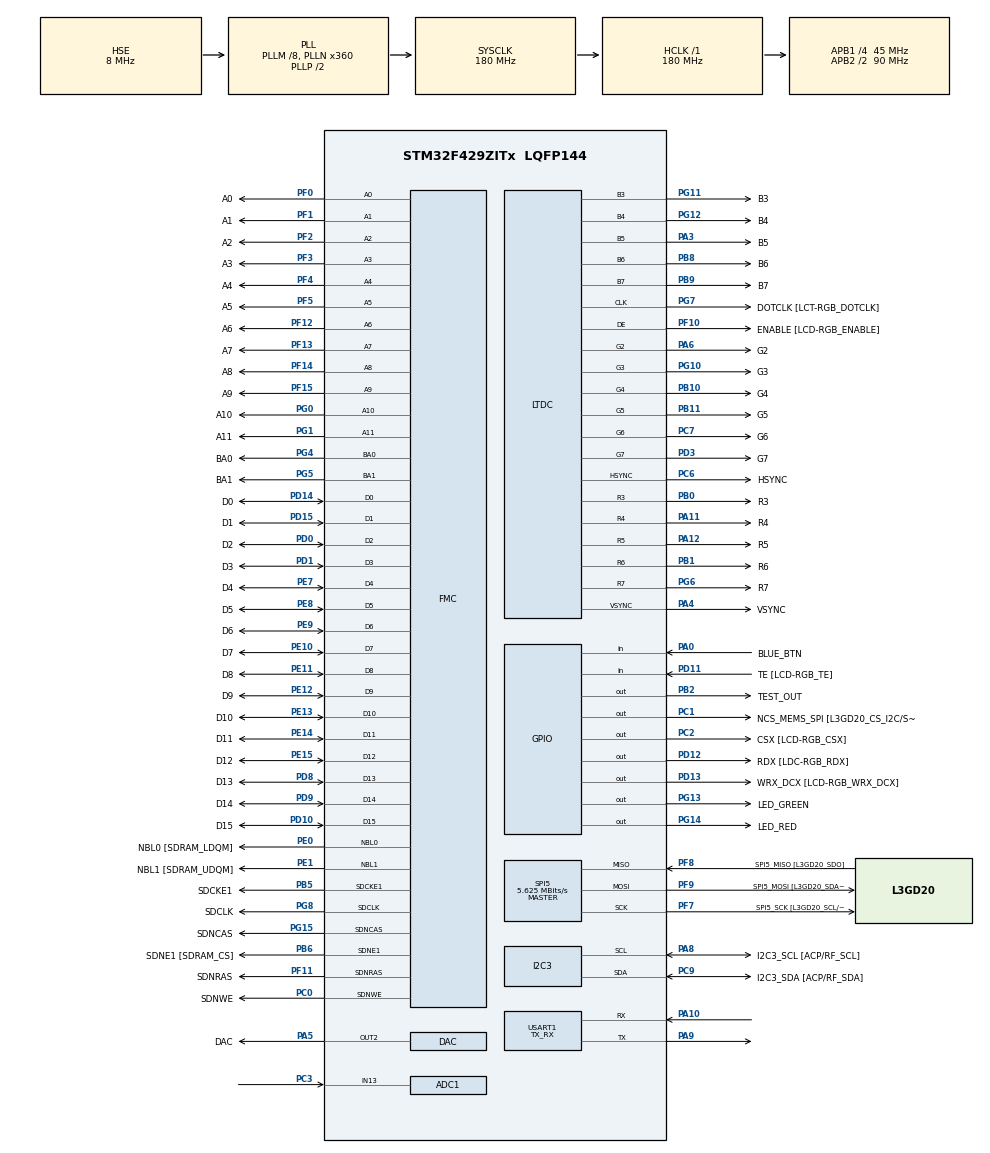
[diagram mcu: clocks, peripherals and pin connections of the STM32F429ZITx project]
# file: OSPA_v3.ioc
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PF5.GPIO_PuPd=GPIO_NOPULL
VP_TIM5_VS_ClockSourceINT.Mode=Internal
PD12.GPIO_Label=RDX [LDC-RGB_RDX]
PC10.GPIO_PuPd=GPIO_NOPULL
FMC.SDClockPeriod2=FMC_SDRAM_CLOCK_PERIOD_2
FMC.SDClockPeriod1=FMC_SDRAM_CLOCK_PERIOD_2
SH.FMC_A0.0=FMC_A0,12b-sda1
PB10.GPIO_PuPd=GPIO_NOPULL
PG8.Signal=FMC_SDCLK
PG0.Signal=FMC_A10
PA3.GPIO_PuPd=GPIO_NOPULL
PE10.GPIO_PuPd=GPIO_NOPULL
PD10.GPIO_PuPd=GPIO_NOPULL
SH.FMC_D5_DA5.0=FMC_D5,sd-16b-d1
PF10.GPIO_PuPd=GPIO_NOPULL
PG10.GPIO_PuPd=GPIO_NOPULL
PA6.GPIO_Mode=GPIO_MODE_AF_PP
SH.FMC_D9_DA9.0=FMC_D9,sd-16b-d1
PG13.GPIO_Mode=GPIO_MODE_OUTPUT_PP
PE13.GPIO_Mode=GPIO_MODE_AF_PP
PF13.GPIO_Mode=GPIO_MODE_AF_PP
PG15.GPIO_Label=SDNCAS
PA4.Mode=RGB565
PF7.Signal=SPI5_SCK
PD13.GPIO_Mode=GPIO_MODE_OUTPUT_PP
NVIC.DMA2D_IRQn=true\:5\:0\:true\:false\:true\:true\:true
SH.FMC_SDNWE.0=FMC_SDNWE,12b-sda1
SH.FMC_D11_DA11.0=FMC_D11,sd-16b-d1
PG7.GPIO_Mode=GPIO_MODE_AF_PP
RCC.APB2TimFreq_Value=180000000
PB6.Signal=FMC_SDNE1
Dma.ADC1.0.Direction=DMA_PERIPH_TO_MEMORY
PC7.Signal=LTDC_G6
PD0.Signal=FMC_D2_DA2
PD8.Signal=FMC_D13_DA13
PE1.Signal=FMC_NBL1
Dma.ADC1.0.MemDataAlignment=DMA_MDATAALIGN_WORD
PF1.GPIO_Label=A1
PC1.GPIO_PuPd=GPIO_NOPULL
PD1.GPIO_Label=D3
FMC.SelfRefreshTime1=4
PF12.GPIO_Label=A6
LTDC.PixelFormat_L0=LTDC_PIXEL_FORMAT_RGB565
LTDC.PixelFormat_L1=LTDC_PIXEL_FORMAT_RGB565
PB1.GPIO_Speed=GPIO_SPEED_FREQ_LOW
PE9.Signal=FMC_D6_DA6
PD1.GPIO_Speed=GPIO_SPEED_FREQ_VERY_HIGH
SH.FMC_A2.0=FMC_A2,12b-sda1
PB1.GPIO_Label=R6
PG4.GPIO_Label=BA0
PC9.Mode=I2C
PD14.GPIO_PuPd=GPIO_NOPULL
PA8.Signal=I2C3_SCL
SH.FMC_D1_DA1.0=FMC_D1,sd-16b-d1
PF1.GPIO_Speed=GPIO_SPEED_FREQ_VERY_HIGH
PF1.GPIO_Mode=GPIO_MODE_AF_PP
LTDC.HSync=10
PF14.GPIO_PuPd=GPIO_NOPULL
PG0.GPIO_PuPd=GPIO_NOPULL
PE9.GPIO_Mode=GPIO_MODE_AF_PP
Mcu.Package=LQFP144
PB9.Signal=LTDC_B7
TIM2.Prescaler=499
PB1.Signal=LTDC_R6
PD12.Signal=GPIO_Output
PA10.Signal=USART1_RX
PB9.GPIO_PuPd=GPIO_NOPULL
PE12.GPIO_Label=D9
FMC.WriteRecoveryTime1=3
PE12.GPIO_Speed=GPIO_SPEED_FREQ_VERY_HIGH
PB5.GPIO_Speed=GPIO_SPEED_FREQ_VERY_HIGH
SPI5.CalculateBaudRate=5.625 MBits/s
PE8.GPIO_Speed=GPIO_SPEED_FREQ_VERY_HIGH
PG8.GPIO_Speed=GPIO_SPEED_FREQ_VERY_HIGH
RCC.APB2CLKDivider=RCC_HCLK_DIV2
LTDC.VSync=2
PF5.GPIO_Speed=GPIO_SPEED_FREQ_VERY_HIGH
RCC.APB1TimFreq_Value=90000000
FMC.RowCycleDelay2=7
PF10.Mode=RGB565
FMC.RowCycleDelay1=7
PD3.GPIO_PuPd=GPIO_NOPULL
PF9.GPIO_PuPd=GPIO_NOPULL
NVIC.DMA1_Stream6_IRQn=true\:0\:0\:false\:false\:true\:false\:true
PA4.GPIO_Label=VSYNC
PA8.GPIO_Speed=GPIO_SPEED_FREQ_LOW
PD15.Signal=FMC_D1_DA1
PG12.Signal=LTDC_B4
PB5.GPIO_Mode=GPIO_MODE_AF_PP
SH.FMC_A4.0=FMC_A4,12b-sda1
PF4.GPIO_Mode=GPIO_MODE_AF_PP
PG5.Signal=FMC_A15_BA1
SH.FMC_D10_DA10.0=FMC_D10,sd-16b-d1
PB6.GPIO_PuPd=GPIO_NOPULL
PD3.Signal=LTDC_G7
PC2.Signal=GPIO_Output
PF5.GPIO_Mode=GPIO_MODE_AF_PP
LTDC.ImageWidth_L1=240
PG8.GPIO_PuPd=GPIO_NOPULL
PF8.GPIO_Label=SPI5_MISO [L3GD20_SDO]
LTDC.ImageWidth_L0=240
PD10.Signal=FMC_D15_DA15
PA3.Mode=RGB565
PC10.GPIO_Mode=GPIO_MODE_AF_PP
PB8.GPIO_Label=B6
PB10.GPIO_Mode=GPIO_MODE_AF_PP
PA8.GPIO_Label=I2C3_SCL [ACP/RF_SCL]
PE8.GPIO_Label=D5
Dma.ADC1.0.Priority=DMA_PRIORITY_VERY_HIGH
PB1.GPIO_Mode=GPIO_MODE_AF_PP
PG10.GPIO_Mode=GPIO_MODE_AF_PP
PA5.Signal=COMP_DAC2_group
PF10.GPIO_Mode=GPIO_MODE_AF_PP
PE1.GPIO_Label=NBL1 [SDRAM_UDQM]
PF15.GPIO_Speed=GPIO_SPEED_FREQ_VERY_HIGH
PF13.GPIO_PuPd=GPIO_NOPULL
FMC.ReadBurst1=FMC_SDRAM_RBURST_DISABLE
SH.FMC_A6.0=FMC_A6,12b-sda1
PE14.Signal=FMC_D11_DA11
PF12.GPIO_Speed=GPIO_SPEED_FREQ_VERY_HIGH
PG7.GPIO_Label=DOTCLK [LCT-RGB_DOTCLK]
PF4.GPIO_Label=A4
PC9.GPIO_PuPd=GPIO_NOPULL
PC1.GPIO_Speed=GPIO_SPEED_FREQ_LOW
PF13.Signal=FMC_A7
TIM2.Period=1439
PG14.GPIO_PuPd=GPIO_NOPULL
PG1.GPIO_Speed=GPIO_SPEED_FREQ_VERY_HIGH
ADC1.ExternalTrigConv=ADC_EXTERNALTRIGCONV_T2_TRGO
PC7.GPIO_Label=G6
ADC1.master=1
PA5.GPIO_Label=DAC
PB5.GPIO_PuPd=GPIO_NOPULL
ProjectManager.HeapSize=0x10
PB1.Mode=RGB565
PD0.GPIO_PuPd=GPIO_NOPULL
PG12.GPIO_Speed=GPIO_SPEED_FREQ_LOW
Dma.DAC2.1.Mode=DMA_CIRCULAR
PD8.GPIO_Speed=GPIO_SPEED_FREQ_VERY_HIGH
NVIC.PriorityGroup=NVIC_PRIORITYGROUP_4
PF0.GPIO_Label=A0
PE15.GPIO_Speed=GPIO_SPEED_FREQ_VERY_HIGH
PF4.Signal=FMC_A4
PD14.GPIO_Mode=GPIO_MODE_AF_PP
PG5.GPIO_Speed=GPIO_SPEED_FREQ_VERY_HIGH
Mcu.Family=STM32F4
LTDC.BlendingFactor1_L1=LTDC_BLENDING_FACTOR1_PAxCA
LTDC.BlendingFactor1_L0=LTDC_BLENDING_FACTOR1_CA
PA6.Mode=RGB565
SH.FMC_A8.0=FMC_A8,12b-sda1
SH.FMC_D14_DA14.0=FMC_D14,sd-16b-d1
PE11.GPIO_Label=D8
PD9.GPIO_Speed=GPIO_SPEED_FREQ_VERY_HIGH
PD0.GPIO_Label=D2
PA11.Mode=RGB565
PF9.GPIO_Speed=GPIO_SPEED_FREQ_LOW
PC2.GPIO_Speed=GPIO_SPEED_FREQ_LOW
SH.FMC_A14_BA0.0=FMC_BA0,FourSdramBanks1
SH.FMC_A11.0=FMC_A11,12b-sda1
PD8.GPIO_PuPd=GPIO_NOPULL
PG5.GPIO_Label=BA1
PG11.Signal=LTDC_B3
PG15.Signal=FMC_SDNCAS
SH.COMP_DAC2_group.0=DAC_OUT2,DAC_OUT2
PD13.Signal=GPIO_Output
PE11.GPIO_PuPd=GPIO_NOPULL
PF11.GPIO_PuPd=GPIO_NOPULL
PB1.GPIO_PuPd=GPIO_NOPULL
PF13.GPIO_Speed=GPIO_SPEED_FREQ_VERY_HIGH
LTDC.WindowX1_L1=240
SH.FMC_NBL1.0=FMC_NBL1,Sd2ByteEnable1
LTDC.WindowX1_L0=240
PG5.GPIO_PuPd=GPIO_NOPULL
RCC.HSE_VALUE=8000000
PA4.GPIO_PuPd=GPIO_NOPULL
FMC.ExitSelfRefreshDelay1=7
PF7.GPIO_Mode=GPIO_MODE_AF_PP
PE13.GPIO_PuPd=GPIO_NOPULL
PA4.GPIO_Speed=GPIO_SPEED_FREQ_LOW
PG11.GPIO_Speed=GPIO_SPEED_FREQ_LOW
PH1/OSC_OUT.GPIO_Label=PH1-OSC_OUT
PA6.GPIO_PuPd=GPIO_NOPULL
PF9.Mode=Full_Duplex_Master
PF7.GPIO_Speed=GPIO_SPEED_FREQ_LOW
PF8.GPIO_PuPd=GPIO_NOPULL
PF11.Signal=FMC_SDNRAS
PB5.Mode=SdramChipSelect2_1
PC7.GPIO_Mode=GPIO_MODE_AF_PP
PG7.GPIO_PuPd=GPIO_NOPULL
PD10.GPIO_Speed=GPIO_SPEED_FREQ_VERY_HIGH
PG4.GPIO_Mode=GPIO_MODE_AF_PP
Dma.DAC2.1.Instance=DMA1_Stream6
PD6.GPIO_Mode=GPIO_MODE_AF_PP
PD13.GPIO_Label=WRX_DCX [LCD-RGB_WRX_DCX]
PA6.Signal=LTDC_G2
PB0.GPIO_Mode=GPIO_MODE_AF_PP
RCC.EnbaleCSS=true
PG1.GPIO_PuPd=GPIO_NOPULL
PF8.Signal=SPI5_MISO
PG0.GPIO_Label=A10
PB5.GPIO_Label=SDCKE1
Dma.Request1=DAC2
PD0.GPIO_Mode=GPIO_MODE_AF_PP
PG14.GPIO_Mode=GPIO_MODE_OUTPUT_PP
PG11.GPIO_Label=B3
PD3.GPIO_Label=G7
PE14.GPIO_Mode=GPIO_MODE_AF_PP
PE7.Signal=FMC_D4_DA4
DAC.TriangleAmplitude2=DAC_TRIANGLEAMPLITUDE_127
PD6.Signal=LTDC_B2
Dma.Request0=ADC1
PF3.GPIO_Label=A3
PA12.GPIO_Speed=GPIO_SPEED_FREQ_LOW
PA3.Signal=LTDC_B5
PE0.GPIO_PuPd=GPIO_NOPULL
PG1.GPIO_Mode=GPIO_MODE_AF_PP
NVIC.LTDC_IRQn=true\:5\:0\:true\:false\:true\:true\:true
SH.ADCx_IN13.0=ADC1_IN13,IN13
LTDC.VFP=4
PD15.GPIO_Label=D1
LTDC.WindowY1_L0=320
PG7.Signal=LTDC_CLK
LTDC.WindowY1_L1=320
PA10.Mode=Asynchronous
PC9.GPIO_Label=I2C3_SDA [ACP/RF_SDA]
Dma.DAC2.1.FIFOMode=DMA_FIFOMODE_DISABLE
PF10.GPIO_Speed=GPIO_SPEED_FREQ_LOW
PE14.GPIO_Label=D11
PD9.Signal=FMC_D14_DA14
SPI5.Mode=SPI_MODE_MASTER
PA12.GPIO_Label=R5
PD8.GPIO_Label=D13
PB0.GPIO_Speed=GPIO_SPEED_FREQ_LOW
PG8.GPIO_Label=SDCLK
Dma.ADC1.0.PeriphDataAlignment=DMA_PDATAALIGN_WORD
PA9.Mode=Asynchronous
PB2/BOOT1.Signal=GPIO_Output
PB10.GPIO_Label=G4
PC9.GPIO_Mode=GPIO_MODE_AF_OD
SH.FMC_D13_DA13.0=FMC_D13,sd-16b-d1
PA3.GPIO_Mode=GPIO_MODE_AF_PP
PG0.GPIO_Speed=GPIO_SPEED_FREQ_VERY_HIGH
PB9.Mode=RGB565
PF9.GPIO_Label=SPI5_MOSI [L3GD20_SDA/SDI/SDO]
PD10.GPIO_Label=D15
PE10.GPIO_Mode=GPIO_MODE_AF_PP
board=STM32F429I-DISC1
PD13.GPIO_Speed=GPIO_SPEED_FREQ_LOW
PG12.Mode=RGB565
PC7.GPIO_Speed=GPIO_SPEED_FREQ_LOW
RCC.VCOOutputFreq_Value=360000000
ADC1.EnableAnalogWatchDog=true
PA4.GPIO_Mode=GPIO_MODE_AF_PP
Dma.DAC2.1.PeriphDataAlignment=DMA_PDATAALIGN_WORD
PF4.GPIO_Speed=GPIO_SPEED_FREQ_VERY_HIGH
PC1.GPIO_Label=NCS_MEMS_SPI [L3GD20_CS_I2C/SPI]
PE11.GPIO_Mode=GPIO_MODE_AF_PP
SH.FMC_D12_DA12.0=FMC_D12,sd-16b-d1
PF15.GPIO_Label=A9
PE14.GPIO_PuPd=GPIO_NOPULL
PF1.Signal=FMC_A1
PF8.GPIO_Mode=GPIO_MODE_AF_PP
PE0.Signal=FMC_NBL0
PE7.GPIO_Label=D4
PE12.Signal=FMC_D9_DA9
PE12.GPIO_Mode=GPIO_MODE_AF_PP
Dma.DAC2.1.Direction=DMA_MEMORY_TO_PERIPH
RCC.48MHZClocksFreq_Value=120000000
RCC.SYSCLKFreq_VALUE=180000000
TIM5.Prescaler=99
Dma.ADC1.0.MemInc=DMA_MINC_ENABLE
PE15.GPIO_PuPd=GPIO_NOPULL
PG4.GPIO_PuPd=GPIO_NOPULL
PD3.GPIO_Mode=GPIO_MODE_AF_PP
RCC.HSI_VALUE=16000000
PA8.GPIO_PuPd=GPIO_NOPULL
PH0/OSC_IN.GPIO_Label=PH0-OSC_IN
PF9.GPIO_Mode=GPIO_MODE_AF_PP
RCC.PLLQ=3
RCC.PLLM=8
RCC.PLLN=360
TIM5.Period=44
PG0.GPIO_Mode=GPIO_MODE_AF_PP
PB8.GPIO_Speed=GPIO_SPEED_FREQ_LOW
PD6.GPIO_Speed=GPIO_SPEED_FREQ_LOW
PG14.GPIO_Speed=GPIO_SPEED_FREQ_LOW
LTDC.ImageHeight_L0=320
LTDC.ImageHeight_L1=320
PB0.GPIO_PuPd=GPIO_NOPULL
PA3.GPIO_Label=B5
PD6.GPIO_PuPd=GPIO_NOPULL
PA11.GPIO_Speed=GPIO_SPEED_FREQ_LOW
PF15.GPIO_Mode=GPIO_MODE_AF_PP
SH.FMC_D7_DA7.0=FMC_D7,sd-16b-d1
PE15.GPIO_Mode=GPIO_MODE_AF_PP
PD1.GPIO_Mode=GPIO_MODE_AF_PP
PD15.GPIO_Mode=GPIO_MODE_AF_PP
PE14.GPIO_Speed=GPIO_SPEED_FREQ_VERY_HIGH
FMC.RCDDelay1=2
PB10.Mode=RGB565
PA8.GPIO_Mode=GPIO_MODE_AF_OD
PG4.Signal=FMC_A14_BA0
PG6.GPIO_Label=R7
PE8.GPIO_PuPd=GPIO_NOPULL
FMC.LoadToActiveDelay1=2
PC6.GPIO_Label=HSYNC
PA6.GPIO_Label=G2
PB6.GPIO_Label=SDNE1 [SDRAM_CS]
PA3.GPIO_Speed=GPIO_SPEED_FREQ_LOW
PD3.GPIO_Speed=GPIO_SPEED_FREQ_LOW
PG6.Mode=RGB565
PD6.GPIO_Label=B2
PG13.Signal=GPIO_Output
TIM4.TIM_MasterOutputTrigger=TIM_TRGO_UPDATE
RCC.SYSCLKSource=RCC_SYSCLKSOURCE_PLLCLK
PG15.GPIO_Mode=GPIO_MODE_AF_PP
PB11.GPIO_Speed=GPIO_SPEED_FREQ_LOW
SH.FMC_A15_BA1.0=FMC_BA1,FourSdramBanks1
PD14.GPIO_Speed=GPIO_SPEED_FREQ_VERY_HIGH
NVIC.TIM5_IRQn=true\:0\:0\:false\:false\:true\:true\:true
PB2/BOOT1.GPIO_Label=TEST_OUT
ADC1.Channel-2\#ChannelRegularConversion=ADC_CHANNEL_13
PH1/OSC_OUT.Signal=RCC_OSC_OUT
PB6.Mode=SdramChipSelect2_1
PC3.Signal=ADCx_IN13
PF10.GPIO_Label=ENABLE [LCD-RGB_ENABLE]
PF14.GPIO_Speed=GPIO_SPEED_FREQ_VERY_HIGH
DAC.DAC_Trigger2=DAC_TRIGGER_T4_TRGO
PG6.GPIO_PuPd=GPIO_NOPULL
PF11.GPIO_Mode=GPIO_MODE_AF_PP
Dma.ADC1.0.PeriphInc=DMA_PINC_DISABLE
PD11.GPIO_Mode=GPIO_MODE_INPUT
PF8.Mode=Full_Duplex_Master
TIM4.Period=1405
PF3.Signal=FMC_A3
PD3.Mode=RGB565
PE10.Signal=FMC_D7_DA7
PF3.GPIO_Speed=GPIO_SPEED_FREQ_VERY_HIGH
PF3.GPIO_PuPd=GPIO_NOPULL
PC6.GPIO_PuPd=GPIO_NOPULL
SH.FMC_A1.0=FMC_A1,12b-sda1
SH.FMC_SDCLK.0=FMC_SDCLK,12b-sda1
PC2.GPIO_Mode=GPIO_MODE_OUTPUT_PP
PG12.GPIO_PuPd=GPIO_NOPULL
PF14.Signal=FMC_A8
VP_DMA2D_VS_DMA2D.Mode=DMA2D_Activate
Dma.ADC1.0.FIFOMode=DMA_FIFOMODE_DISABLE
PA6.GPIO_Speed=GPIO_SPEED_FREQ_LOW
PB11.GPIO_Mode=GPIO_MODE_AF_PP
NVIC.USART1_IRQn=true\:0\:0\:false\:false\:true\:true\:true
PA12.GPIO_PuPd=GPIO_NOPULL
PE10.GPIO_Label=D7
PD9.GPIO_PuPd=GPIO_NOPULL
PC6.GPIO_Speed=GPIO_SPEED_FREQ_LOW
SH.FMC_D3_DA3.0=FMC_D3,sd-16b-d1
SPI5.VirtualType=VM_MASTER
PG6.GPIO_Speed=GPIO_SPEED_FREQ_LOW
PE12.GPIO_PuPd=GPIO_NOPULL
PD8.GPIO_Mode=GPIO_MODE_AF_PP
Dma.ADC1.0.Instance=DMA2_Stream0
PD9.GPIO_Label=D14
PE11.GPIO_Speed=GPIO_SPEED_FREQ_VERY_HIGH
PD9.GPIO_Mode=GPIO_MODE_AF_PP
PB8.GPIO_PuPd=GPIO_NOPULL
PC6.Signal=LTDC_HSYNC
PB11.GPIO_Label=G5
PD1.Signal=FMC_D3_DA3
PA11.GPIO_Label=R4
PE1.GPIO_PuPd=GPIO_NOPULL
PF14.GPIO_Label=A8
Dma.DAC2.1.Priority=DMA_PRIORITY_HIGH
PD1.GPIO_PuPd=GPIO_NOPULL
PC0.Signal=FMC_SDNWE
RCC.APB1CLKDivider=RCC_HCLK_DIV4
PF13.GPIO_Label=A7
PG13.GPIO_Label=LED_GREEN
PD0.GPIO_Speed=GPIO_SPEED_FREQ_VERY_HIGH
PG10.Signal=LTDC_G3
PE0.GPIO_Speed=GPIO_SPEED_FREQ_VERY_HIGH
PF11.GPIO_Speed=GPIO_SPEED_FREQ_VERY_HIGH
SH.FMC_A3.0=FMC_A3,12b-sda1
TIM5.TIM_MasterOutputTrigger=TIM_TRGO_UPDATE
FMC.CASLatency1=FMC_SDRAM_CAS_LATENCY_3
PF2.GPIO_Mode=GPIO_MODE_AF_PP
PB11.Mode=RGB565
SH.FMC_D15_DA15.0=FMC_D15,sd-16b-d1
PC6.Mode=RGB565
PA9.Signal=USART1_TX
PC7.GPIO_PuPd=GPIO_NOPULL
PE9.GPIO_Label=D6
PB10.Signal=LTDC_G4
PE7.GPIO_Speed=GPIO_SPEED_FREQ_VERY_HIGH
PE15.Signal=FMC_D12_DA12
PG11.GPIO_Mode=GPIO_MODE_AF_PP
USART1.Mode=MODE_TX_RX
PE8.Signal=FMC_D5_DA5
PG5.GPIO_Mode=GPIO_MODE_AF_PP
PA0/WKUP.GPIO_Label=BLUE_BTN
PC6.GPIO_Mode=GPIO_MODE_AF_PP
ADC1.DMAContinuousRequests=ENABLE
PG14.GPIO_Label=LED_RED
SH.FMC_SDNCAS.0=FMC_SDNCAS,12b-sda1
PG12.GPIO_Mode=GPIO_MODE_AF_PP
PF7.GPIO_PuPd=GPIO_NOPULL
PA4.Signal=LTDC_VSYNC
PB5.Signal=FMC_SDCKE1
PE13.GPIO_Label=D10
PD11.Signal=GPIO_Input
USART1.VirtualMode=VM_ASYNC
SH.FMC_A5.0=FMC_A5,12b-sda1
PG11.Mode=RGB565
LTDC.Alpha_L0=255
PA11.Signal=LTDC_R4
PF9.Signal=SPI5_MOSI
VP_TIM4_VS_ClockSourceINT.Mode=Internal
PC9.GPIO_Speed=GPIO_SPEED_FREQ_LOW
PB8.Mode=RGB565
PF12.GPIO_PuPd=GPIO_NOPULL
TIM2.AutoReloadPreload=TIM_AUTORELOAD_PRELOAD_ENABLE
PA8.Mode=I2C
DAC.WaveGeneration2=TriangleWaveGeneration
PB6.GPIO_Speed=GPIO_SPEED_FREQ_VERY_HIGH
Dma.DAC2.1.MemInc=DMA_MINC_ENABLE
PG6.GPIO_Mode=GPIO_MODE_AF_PP
PB0.Signal=LTDC_R3
PE0.GPIO_Mode=GPIO_MODE_AF_PP
PC1.Signal=GPIO_Output
PF3.GPIO_Mode=GPIO_MODE_AF_PP
PG10.GPIO_Label=G3
PG15.GPIO_PuPd=GPIO_NOPULL
PE7.GPIO_PuPd=GPIO_NOPULL
RCC.CortexFreq_Value=180000000
PG6.Signal=LTDC_R7
PB10.GPIO_Speed=GPIO_SPEED_FREQ_LOW
PB6.GPIO_Mode=GPIO_MODE_AF_PP
RCC.PLLSAIDivR=RCC_PLLSAIDIVR_8
LTDC.HBP=20
PD15.GPIO_Speed=GPIO_SPEED_FREQ_VERY_HIGH
PC10.Signal=LTDC_R2
PF4.GPIO_PuPd=GPIO_NOPULL
SH.FMC_NBL0.0=FMC_NBL0,Sd2ByteEnable1
SH.FMC_D6_DA6.0=FMC_D6,sd-16b-d1
PC0.GPIO_Label=SDNWE
Dma.DAC2.1.PeriphInc=DMA_PINC_DISABLE
PE9.GPIO_Speed=GPIO_SPEED_FREQ_VERY_HIGH
PA0/WKUP.Signal=GPIO_Input
PB0.GPIO_Label=R3
PC10.GPIO_Speed=GPIO_SPEED_FREQ_LOW
PA11.GPIO_PuPd=GPIO_NOPULL
PB11.GPIO_PuPd=GPIO_NOPULL
PB11.Signal=LTDC_G5
PG8.GPIO_Mode=GPIO_MODE_AF_PP
PF2.GPIO_Speed=GPIO_SPEED_FREQ_VERY_HIGH
ProjectManager.StackSize=0x10
PD11.GPIO_PuPd=GPIO_NOPULL
SH.FMC_A7.0=FMC_A7,12b-sda1
PA12.Signal=LTDC_R5
PE1.GPIO_Mode=GPIO_MODE_AF_PP
PH0/OSC_IN.Mode=HSE-External-Oscillator
PG11.GPIO_PuPd=GPIO_NOPULL
PD11.GPIO_Label=TE [LCD-RGB_TE]
RCC.HCLKFreq_Value=180000000
PF11.GPIO_Label=SDNRAS
PF2.GPIO_PuPd=GPIO_NOPULL
PF12.Signal=FMC_A6
NVIC.DMA2_Stream0_IRQn=true\:0\:0\:false\:false\:true\:false\:true
SH.FMC_A10.0=FMC_A10,12b-sda1
RCC.AHBFreq_Value=180000000
PC1.GPIO_Mode=GPIO_MODE_OUTPUT_PP
SH.FMC_D8_DA8.0=FMC_D8,sd-16b-d1
FMC.RPDelay2=2
FMC.RPDelay1=2
PG13.GPIO_PuPd=GPIO_NOPULL
SH.FMC_D2_DA2.0=FMC_D2,sd-16b-d1
ADC1.Rank-2\#ChannelRegularConversion=1
PE13.Signal=FMC_D10_DA10
PF7.GPIO_Label=SPI5_SCK [L3GD20_SCL/SPC]
PG4.GPIO_Speed=GPIO_SPEED_FREQ_VERY_HIGH
LTDC.HFP=10
LTDC.BlendingFactor2_L0=LTDC_BLENDING_FACTOR2_CA
LTDC.BlendingFactor2_L1=LTDC_BLENDING_FACTOR2_PAxCA
FMC.ReadPipeDelay1=FMC_SDRAM_RPIPE_DELAY_1
FMC.ReadPipeDelay2=FMC_SDRAM_RPIPE_DELAY_1
PE10.GPIO_Speed=GPIO_SPEED_FREQ_VERY_HIGH
SH.FMC_SDNRAS.0=FMC_SDNRAS,12b-sda1
DMA2D.ColorMode=DMA2D_OUTPUT_RGB565
LTDC.ActiveW=240
PH1/OSC_OUT.Mode=HSE-External-Oscillator
PF12.GPIO_Mode=GPIO_MODE_AF_PP
PD12.GPIO_Mode=GPIO_MODE_OUTPUT_PP
SPI5.BaudRatePrescaler=SPI_BAUDRATEPRESCALER_16
SH.FMC_D0_DA0.0=FMC_D0,sd-16b-d1
PG15.GPIO_Speed=GPIO_SPEED_FREQ_VERY_HIGH
PF15.GPIO_PuPd=GPIO_NOPULL
PD15.GPIO_PuPd=GPIO_NOPULL
PF5.GPIO_Label=A5
SH.FMC_A9.0=FMC_A9,12b-sda1
SH.FMC_D4_DA4.0=FMC_D4,sd-16b-d1
PE8.GPIO_Mode=GPIO_MODE_AF_PP
PE0.GPIO_Label=NBL0 [SDRAM_LDQM]
RCC.PLLSAIN=192
PF5.Signal=FMC_A5
RCC.PLLSAIR=4
TIM2.TIM_MasterOutputTrigger=TIM_TRGO_UPDATE
PB9.GPIO_Speed=GPIO_SPEED_FREQ_LOW
PG13.GPIO_Speed=GPIO_SPEED_FREQ_LOW
PF0.Signal=FMC_A0
PC0.GPIO_PuPd=GPIO_NOPULL
PC2.GPIO_Label=CSX [LCD-RGB_CSX]
Dma.DAC2.1.MemDataAlignment=DMA_MDATAALIGN_WORD
PF0.GPIO_Mode=GPIO_MODE_AF_PP
RCC.PLLSourceVirtual=RCC_PLLSOURCE_HSE
I2C3.I2C_Mode=I2C_Fast
LTDC.FBStartAdress_L0=0xD0000000
LTDC.FBStartAdress_L1=0xD0025800
PD12.GPIO_Speed=GPIO_SPEED_FREQ_LOW
PB9.GPIO_Label=B7
PC10.GPIO_Label=R2
PG1.Signal=FMC_A11
PG10.Mode=RGB565
PG10.GPIO_Speed=GPIO_SPEED_FREQ_LOW
ADC1.SamplingTime-2\#ChannelRegularConversion=ADC_SAMPLETIME_3CYCLES
PF0.GPIO_Speed=GPIO_SPEED_FREQ_VERY_HIGH
PD10.GPIO_Mode=GPIO_MODE_AF_PP
PF7.Mode=Full_Duplex_Master
PC0.GPIO_Speed=GPIO_SPEED_FREQ_VERY_HIGH
PE15.GPIO_Label=D12
ProjectManager.TargetToolchain=STM32CubeIDE
Dma.ADC1.0.Mode=DMA_CIRCULAR
LTDC.ActiveH=320
PF2.Signal=FMC_A2
PE11.Signal=FMC_D8_DA8
PG7.Mode=RGB565
RCC.LSE_VALUE=32768
PE7.GPIO_Mode=GPIO_MODE_AF_PP
PG14.Signal=GPIO_Output
PB0.Mode=RGB565
PG1.GPIO_Label=A11
PB9.GPIO_Mode=GPIO_MODE_AF_PP
PA12.GPIO_Mode=GPIO_MODE_AF_PP
PH0/OSC_IN.Signal=RCC_OSC_IN
PG7.GPIO_Speed=GPIO_SPEED_FREQ_LOW
RCC.APB2Freq_Value=90000000
PC0.GPIO_Mode=GPIO_MODE_AF_PP
LTDC.Layers=1
VP_TIM2_VS_ClockSourceINT.Mode=Internal
PF10.Signal=LTDC_DE
PE1.GPIO_Speed=GPIO_SPEED_FREQ_VERY_HIGH
PF1.GPIO_PuPd=GPIO_NOPULL
PD13.GPIO_PuPd=GPIO_NOPULL
PF15.Signal=FMC_A9
PD14.GPIO_Label=D0
PC2.GPIO_PuPd=GPIO_NOPULL
Mcu.Name=STM32F429ZITx
PD14.Signal=FMC_D0_DA0
PF0.GPIO_PuPd=GPIO_NOPULL
PA12.Mode=RGB565
PG12.GPIO_Label=B4
ADC1.WatchdogChannel=ADC_CHANNEL_13
ADC1.NbrOfConversionFlag=1
PF8.GPIO_Speed=GPIO_SPEED_FREQ_LOW
PE13.GPIO_Speed=GPIO_SPEED_FREQ_VERY_HIGH
PB8.Signal=LTDC_B6
PF14.GPIO_Mode=GPIO_MODE_AF_PP
PC9.Signal=I2C3_SDA
PC7.Mode=RGB565
PA11.GPIO_Mode=GPIO_MODE_AF_PP
PB8.GPIO_Mode=GPIO_MODE_AF_PP
RCC.APB1Freq_Value=45000000
PD12.GPIO_PuPd=GPIO_NOPULL
SPI5.Direction=SPI_DIRECTION_2LINES
PE9.GPIO_PuPd=GPIO_NOPULL
PF2.GPIO_Label=A2

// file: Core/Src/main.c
/* USER CODE BEGIN Header */
/**
  ******************************************************************************
  * @file           : main.c
  * @brief          : Main program body
  ******************************************************************************
  * @attention
  *
  * <h2><center>&copy; Copyright (c) 2020 STMicroelectronics.
  * All rights reserved.</center></h2>
  *
  * This software component is licensed by ST under Ultimate Liberty license
  * SLA0044, the "License"; You may not use this file except in compliance with
  * the License. You may obtain a copy of the License at:
  *                             www.st.com/SLA0044
  *
  ******************************************************************************
  */
/* USER CODE END Header */
#include "main.h"

/* USER CODE BEGIN Includes */
#include "ospa.h"
#include "stm32_ub_sdram.h"
#include "generator.h"
/* USER CODE END Includes */

ADC_HandleTypeDef hadc1;
DMA_HandleTypeDef hdma_adc1;

DAC_HandleTypeDef hdac;
DMA_HandleTypeDef hdma_dac2;

DMA2D_HandleTypeDef hdma2d;

I2C_HandleTypeDef hi2c3;

LTDC_HandleTypeDef hltdc;

SPI_HandleTypeDef hspi5;

TIM_HandleTypeDef htim2;
TIM_HandleTypeDef htim4;
TIM_HandleTypeDef htim5;

UART_HandleTypeDef huart1;

SDRAM_HandleTypeDef hsdram1;

/* USER CODE BEGIN PV */
uint8_t Received;
uint8_t tmp[2];
/* USER CODE END PV */

void SystemClock_Config(void);
static void MX_GPIO_Init(void);
static void MX_DMA_Init(void);
static void MX_DMA2D_Init(void);
static void MX_FMC_Init(void);
static void MX_I2C3_Init(void);
static void MX_LTDC_Init(void);
static void MX_ADC1_Init(void);
static void MX_TIM2_Init(void);
static void MX_SPI5_Init(void);
static void MX_TIM5_Init(void);
static void MX_USART1_UART_Init(void);
static void MX_DAC_Init(void);
static void MX_TIM4_Init(void);
/* USER CODE BEGIN PFP */
void HAL_UART_RxCpltCallback(UART_HandleTypeDef * husart);
/* USER CODE END PFP */

/* USER CODE BEGIN 0 */
//arm_rfft_instance_f32 SS;
arm_rfft_fast_instance_f32 SS;
arm_cfft_radix4_instance_f32 S_CFFTT;
//PDMFilter_InitStruct Filter;

uint8_t  PDM_Input_Buffer[PDM_Input_Buffer_SIZE];
uint16_t PCM_Output_Buffer[PCM_Output_Buffer_SIZE];

float32_t buffer_input[1024];
float32_t buffer_input_copy[256];
float32_t buffer_output[1024];
float32_t buffer_output_mag[1024];
float32_t buffer_output_mag_copy[256];
extern uint8_t stop_flag;
extern uint8_t frequency;
extern uint8_t voltage_amp ;
extern uint8_t maxvalueindex;
extern float max_value_conv;
extern float min_value_conv;

int _write(int file, char *ptr, int len)
{
   HAL_UART_Transmit(&huart1, (uint8_t*)ptr, len,HAL_MAX_DELAY);
  // HAL_UART_Transmit_IT(&huart1, (uint8_t*)ptr, len);
  // HAL_UART_Transmit(&huart1,ptr, count,3000) !=HAL_OK
 //  AL_UART_Transmit(&huart1,ptr, count,3000
 return len;
}
void HAL_TIM_PeriodElapsedCallback(TIM_HandleTypeDef *htim) {
	if(htim == &htim2) {

		  printf("htim2 sie wywolal\r\n");
	}

}

/* USER CODE END 0 */

int main(void)
{
  /* USER CODE BEGIN 1 */

	// For freezing the timers when debugging (If the core halts, also do the timers)
	 __HAL_DBGMCU_FREEZE_TIM2();
	 __HAL_DBGMCU_FREEZE_TIM5();
  /* USER CODE END 1 */

  /* MCU Configuration--------------------------------------------------------*/

  /* Reset of all peripherals, Initializes the Flash interface and the Systick. */
  HAL_Init();

  /* Configure the system clock */
  SystemClock_Config();

  /* Initialize all configured peripherals */
  MX_GPIO_Init();
  MX_DMA_Init();
  MX_DMA2D_Init();
  MX_FMC_Init();
  MX_I2C3_Init();
  MX_LTDC_Init();
  MX_ADC1_Init();
  MX_TIM2_Init();
  MX_SPI5_Init();
  MX_TIM5_Init();
  MX_USART1_UART_Init();
  MX_DAC_Init();
  MX_TIM4_Init();
  /* USER CODE BEGIN 2 */
 // HAL_DAC_Start_DMA(&hdac, DAC_CHANNEL_1, (uint32_t*)Wave_LUT, 128, DAC_ALIGN_12B_R);
  HAL_TIM_Base_Start(&htim2);
  HAL_UART_Receive_IT(&huart1, &Received, 1);
  //HAL_UART_Receive(&huart1, &Received, 1,HAL_MAX_DELAY);

  tmp[0]=0;
  ospa_init();
  ospa_start();
  uint16_t xp = 115;
  uint32_t color = 0xF81F;
  uint16_t m=1;
  unsigned int freq, i, z;
  float dt;
  uint32_t  maxvalueindex;
  float32_t maxvalue;
  uint8_t   mode;
  double freq_calc=0;
  //arm_rfft_init_f32(&SS, &S_CFFTT, 512, 0, 1);
  //arm_rfft_fast_init_f32(&SS, 512);
  //printf("po innit \r\n");

  /* USER CODE END 2 */

  /* Infinite loop */
  /* USER CODE BEGIN WHILE */
  printf("petelka sie wywolala\r\n");
  while (1)
{

    /* USER CODE END WHILE */

    /* USER CODE BEGIN 3 */

	  /*

	  if(Timer_ms==0) {
	       Timer_ms=INTERVALL_MS;

	 // printf("HEJJJJ \r\n");

	    dt = 0.0001;
	    freq = 0;
	    mode = 1;
	    ospa_clear_all();
	  for(i=0; i<256; ++i){
	        buffer_input_copy[i] = 0;
	        buffer_output_mag_copy[i] = 0;
	      }
	   int freq_temp=10;
	  while(mode == 1 || mode == 2 || mode == 3 || mode == 4){

	        ++freq;
	        if(freq > 1024)
	         freq = 1;

	        if(freq%20==0)
	        	freq_temp+=20;;
	        if(freq_temp>1024)
	        	freq_temp=1;
	  if(mode == 1){
	     for(i=0; i<512; ++i){
	     buffer_input[i] = (float32_t) 30*sin(2*PI*freq*i*dt);
	     }

	    }
	  //ospa_draw_background();
	  //ospa_clear_all();
	  //UB_LCD_SetLayer_Menu();

	  UB_LCD_SetLayer_2();
	  //UB_Graphic2D_DrawLineNormal(ch1_data1,SCALE_START_Y+n,ch1_data2,SCALE_START_Y+n+1,ADC_CH1_COL);
      for(i=0; i<255; ++i){
    	  UB_Graphic2D_DrawLineNormal((uint16_t)(buffer_input[i] + 100),i+0, (uint16_t)(buffer_input[i+1] + 100), i+1,  color);
//        x_LCD_DrawLine_2(i + 0, (uint16_t)(buffer_input[i] + 30),i + 1, (uint16_t)(buffer_input[i+1] + 30));
      }

	  //p_ospa_draw_adc();
      for(i=0; i<256; ++i){
        buffer_input_copy[i] = buffer_input[i];
        buffer_output_mag_copy[i] = buffer_output_mag[i];
      }

      // Calculate Real FFT

            //arm_rfft_f32(&SS, buffer_input, buffer_output);
            arm_rfft_fast_f32(&SS, buffer_input,  buffer_output, 1);
            //arm_rfft_fast_f32(&SS, buffer_input,  buffer_output, 1);
            // Calculate magnitude
            arm_cmplx_mag_f32(buffer_output, buffer_output_mag, 512);//here are real and imaginary values
            // Get maximum value of magnitude

            arm_max_f32(buffer_output_mag, 512, &maxvalue, &maxvalueindex);
            // Scale magnitude values
            for(i=0; i<512; ++i){
              buffer_output_mag[i] = 100*buffer_output_mag[i]/maxvalue;
            }
      //delay
            //ospa_send_uart((uint8_t *)"Rozpoczynam szukanie czestotliwosci sygnalu.\r\n");
           // for(i=0; i<256; ++i){
            //if( (uint16_t)((uint16_t)buffer_output_mag[i+1]) >50)
           // ospa_send_uart((uint8_t *)"Znaleziono czestotliwosc ");
            //  printf("%f \r\n",buffer_output_mag[i+1]);
           // }
            double new_freq_calc = (maxvalueindex+1)*10.0/512;
            if(freq_calc != new_freq_calc){
            printf("Znaleziona czestotliwosc: %lf kHz\r\n", new_freq_calc);
			//(maxvalueindex+1)*32.0/512)
            freq_calc=new_freq_calc;
            }

	  }

	  //UB_Graphic2D_DrawLineNormal(10,10,200,200,color);
	  UB_LCD_SetLayer_Back();

	  //ospa_draw_line_h(xp,color,m);

	  }//everything up to here in 50ms loop

	  */

	  HAL_Delay(100);
  }
  /* USER CODE END 3 */
}

void SystemClock_Config(void)
{
  RCC_OscInitTypeDef RCC_OscInitStruct = {0};
  RCC_ClkInitTypeDef RCC_ClkInitStruct = {0};
  RCC_PeriphCLKInitTypeDef PeriphClkInitStruct = {0};

  /** Configure the main internal regulator output voltage
  */
  __HAL_RCC_PWR_CLK_ENABLE();
  __HAL_PWR_VOLTAGESCALING_CONFIG(PWR_REGULATOR_VOLTAGE_SCALE1);
  /** Initializes the RCC Oscillators according to the specified parameters
  * in the RCC_OscInitTypeDef structure.
  */
  RCC_OscInitStruct.OscillatorType = RCC_OSCILLATORTYPE_HSE;
  RCC_OscInitStruct.HSEState = RCC_HSE_ON;
  RCC_OscInitStruct.PLL.PLLState = RCC_PLL_ON;
  RCC_OscInitStruct.PLL.PLLSource = RCC_PLLSOURCE_HSE;
  RCC_OscInitStruct.PLL.PLLM = 8;
  RCC_OscInitStruct.PLL.PLLN = 360;
  RCC_OscInitStruct.PLL.PLLP = RCC_PLLP_DIV2;
  RCC_OscInitStruct.PLL.PLLQ = 3;
  if (HAL_RCC_OscConfig(&RCC_OscInitStruct) != HAL_OK)
  {
    Error_Handler();
  }
  /** Activate the Over-Drive mode
  */
  if (HAL_PWREx_EnableOverDrive() != HAL_OK)
  {
    Error_Handler();
  }
  /** Initializes the CPU, AHB and APB buses clocks
  */
  RCC_ClkInitStruct.ClockType = RCC_CLOCKTYPE_HCLK|RCC_CLOCKTYPE_SYSCLK
                              |RCC_CLOCKTYPE_PCLK1|RCC_CLOCKTYPE_PCLK2;
  RCC_ClkInitStruct.SYSCLKSource = RCC_SYSCLKSOURCE_PLLCLK;
  RCC_ClkInitStruct.AHBCLKDivider = RCC_SYSCLK_DIV1;
  RCC_ClkInitStruct.APB1CLKDivider = RCC_HCLK_DIV4;
  RCC_ClkInitStruct.APB2CLKDivider = RCC_HCLK_DIV2;

  if (HAL_RCC_ClockConfig(&RCC_ClkInitStruct, FLASH_LATENCY_5) != HAL_OK)
  {
    Error_Handler();
  }
  PeriphClkInitStruct.PeriphClockSelection = RCC_PERIPHCLK_LTDC;
  PeriphClkInitStruct.PLLSAI.PLLSAIN = 192;
  PeriphClkInitStruct.PLLSAI.PLLSAIR = 4;
  PeriphClkInitStruct.PLLSAIDivR = RCC_PLLSAIDIVR_8;
  if (HAL_RCCEx_PeriphCLKConfig(&PeriphClkInitStruct) != HAL_OK)
  {
    Error_Handler();
  }
  /** Enables the Clock Security System
  */
  HAL_RCC_EnableCSS();
}

static void MX_ADC1_Init(void)
{

  ADC_AnalogWDGConfTypeDef AnalogWDGConfig = {0};
  ADC_ChannelConfTypeDef sConfig = {0};

  /** Configure the global features of the ADC (Clock, Resolution, Data Alignment and number of conversion)
  */
  hadc1.Instance = ADC1;
  hadc1.Init.ClockPrescaler = ADC_CLOCK_SYNC_PCLK_DIV4;
  hadc1.Init.Resolution = ADC_RESOLUTION_12B;
  hadc1.Init.ScanConvMode = DISABLE;
  hadc1.Init.ContinuousConvMode = DISABLE;
  hadc1.Init.DiscontinuousConvMode = DISABLE;
  hadc1.Init.ExternalTrigConvEdge = ADC_EXTERNALTRIGCONVEDGE_RISING;
  hadc1.Init.ExternalTrigConv = ADC_EXTERNALTRIGCONV_T2_TRGO;
  hadc1.Init.DataAlign = ADC_DATAALIGN_RIGHT;
  hadc1.Init.NbrOfConversion = 1;
  hadc1.Init.DMAContinuousRequests = ENABLE;
  hadc1.Init.EOCSelection = ADC_EOC_SINGLE_CONV;
  if (HAL_ADC_Init(&hadc1) != HAL_OK)
  {
    Error_Handler();
  }
  /** Configure the analog watchdog
  */
  AnalogWDGConfig.WatchdogMode = ADC_ANALOGWATCHDOG_SINGLE_REG;
  AnalogWDGConfig.HighThreshold = 0;
  AnalogWDGConfig.LowThreshold = 0;
  AnalogWDGConfig.Channel = ADC_CHANNEL_13;
  AnalogWDGConfig.ITMode = DISABLE;
  if (HAL_ADC_AnalogWDGConfig(&hadc1, &AnalogWDGConfig) != HAL_OK)
  {
    Error_Handler();
  }
  /** Configure for the selected ADC regular channel its corresponding rank in the sequencer and its sample time.
  */
  sConfig.Channel = ADC_CHANNEL_13;
  sConfig.Rank = 1;
  sConfig.SamplingTime = ADC_SAMPLETIME_3CYCLES;
  if (HAL_ADC_ConfigChannel(&hadc1, &sConfig) != HAL_OK)
  {
    Error_Handler();
  }

}

static void MX_DAC_Init(void)
{

  DAC_ChannelConfTypeDef sConfig = {0};

  /** DAC Initialization
  */
  hdac.Instance = DAC;
  if (HAL_DAC_Init(&hdac) != HAL_OK)
  {
    Error_Handler();
  }
  /** DAC channel OUT2 config
  */
  sConfig.DAC_Trigger = DAC_TRIGGER_T4_TRGO;
  sConfig.DAC_OutputBuffer = DAC_OUTPUTBUFFER_ENABLE;
  if (HAL_DAC_ConfigChannel(&hdac, &sConfig, DAC_CHANNEL_2) != HAL_OK)
  {
    Error_Handler();
  }
  /** Configure Triangle wave generation on DAC OUT2
  */
  if (HAL_DACEx_TriangleWaveGenerate(&hdac, DAC_CHANNEL_2, DAC_TRIANGLEAMPLITUDE_127) != HAL_OK)
  {
    Error_Handler();
  }

}

static void MX_DMA2D_Init(void)
{

  hdma2d.Instance = DMA2D;
  hdma2d.Init.Mode = DMA2D_M2M;
  hdma2d.Init.ColorMode = DMA2D_OUTPUT_RGB565;
  hdma2d.Init.OutputOffset = 0;
  hdma2d.LayerCfg[1].InputOffset = 0;
  hdma2d.LayerCfg[1].InputColorMode = DMA2D_INPUT_RGB565;
  hdma2d.LayerCfg[1].AlphaMode = DMA2D_NO_MODIF_ALPHA;
  hdma2d.LayerCfg[1].InputAlpha = 0;
  if (HAL_DMA2D_Init(&hdma2d) != HAL_OK)
  {
    Error_Handler();
  }
  if (HAL_DMA2D_ConfigLayer(&hdma2d, 1) != HAL_OK)
  {
    Error_Handler();
  }

}

static void MX_I2C3_Init(void)
{

  hi2c3.Instance = I2C3;
  hi2c3.Init.ClockSpeed = 400000;
  hi2c3.Init.DutyCycle = I2C_DUTYCYCLE_2;
  hi2c3.Init.OwnAddress1 = 0;
  hi2c3.Init.AddressingMode = I2C_ADDRESSINGMODE_7BIT;
  hi2c3.Init.DualAddressMode = I2C_DUALADDRESS_DISABLE;
  hi2c3.Init.OwnAddress2 = 0;
  hi2c3.Init.GeneralCallMode = I2C_GENERALCALL_DISABLE;
  hi2c3.Init.NoStretchMode = I2C_NOSTRETCH_DISABLE;
  if (HAL_I2C_Init(&hi2c3) != HAL_OK)
  {
    Error_Handler();
  }
  /** Configure Analogue filter
  */
  if (HAL_I2CEx_ConfigAnalogFilter(&hi2c3, I2C_ANALOGFILTER_ENABLE) != HAL_OK)
  {
    Error_Handler();
  }
  /** Configure Digital filter
  */
  if (HAL_I2CEx_ConfigDigitalFilter(&hi2c3, 0) != HAL_OK)
  {
    Error_Handler();
  }

}

static void MX_LTDC_Init(void)
{

  LTDC_LayerCfgTypeDef pLayerCfg = {0};
  LTDC_LayerCfgTypeDef pLayerCfg1 = {0};

  hltdc.Instance = LTDC;
  hltdc.Init.HSPolarity = LTDC_HSPOLARITY_AL;
  hltdc.Init.VSPolarity = LTDC_VSPOLARITY_AL;
  hltdc.Init.DEPolarity = LTDC_DEPOLARITY_AL;
  hltdc.Init.PCPolarity = LTDC_PCPOLARITY_IPC;
  hltdc.Init.HorizontalSync = 9;
  hltdc.Init.VerticalSync = 1;
  hltdc.Init.AccumulatedHBP = 29;
  hltdc.Init.AccumulatedVBP = 3;
  hltdc.Init.AccumulatedActiveW = 269;
  hltdc.Init.AccumulatedActiveH = 323;
  hltdc.Init.TotalWidth = 279;
  hltdc.Init.TotalHeigh = 327;
  hltdc.Init.Backcolor.Blue = 0;
  hltdc.Init.Backcolor.Green = 0;
  hltdc.Init.Backcolor.Red = 0;
  if (HAL_LTDC_Init(&hltdc) != HAL_OK)
  {
    Error_Handler();
  }
  pLayerCfg.WindowX0 = 0;
  pLayerCfg.WindowX1 = 240;
  pLayerCfg.WindowY0 = 0;
  pLayerCfg.WindowY1 = 320;
  pLayerCfg.PixelFormat = LTDC_PIXEL_FORMAT_RGB565;
  pLayerCfg.Alpha = 255;
  pLayerCfg.Alpha0 = 0;
  pLayerCfg.BlendingFactor1 = LTDC_BLENDING_FACTOR1_CA;
  pLayerCfg.BlendingFactor2 = LTDC_BLENDING_FACTOR2_CA;
  pLayerCfg.FBStartAdress = 0xD0000000;
  pLayerCfg.ImageWidth = 240;
  pLayerCfg.ImageHeight = 320;
  pLayerCfg.Backcolor.Blue = 0;
  pLayerCfg.Backcolor.Green = 0;
  pLayerCfg.Backcolor.Red = 0;
  if (HAL_LTDC_ConfigLayer(&hltdc, &pLayerCfg, 0) != HAL_OK)
  {
    Error_Handler();
  }
  pLayerCfg1.WindowX0 = 0;
  pLayerCfg1.WindowX1 = 240;
  pLayerCfg1.WindowY0 = 0;
  pLayerCfg1.WindowY1 = 320;
  pLayerCfg1.PixelFormat = LTDC_PIXEL_FORMAT_RGB565;
  pLayerCfg1.Alpha = 0;
  pLayerCfg1.Alpha0 = 0;
  pLayerCfg1.BlendingFactor1 = LTDC_BLENDING_FACTOR1_PAxCA;
  pLayerCfg1.BlendingFactor2 = LTDC_BLENDING_FACTOR2_PAxCA;
  pLayerCfg1.FBStartAdress = 0xD0025800;
  pLayerCfg1.ImageWidth = 240;
  pLayerCfg1.ImageHeight = 320;
  pLayerCfg1.Backcolor.Blue = 0;
  pLayerCfg1.Backcolor.Green = 0;
  pLayerCfg1.Backcolor.Red = 0;
  if (HAL_LTDC_ConfigLayer(&hltdc, &pLayerCfg1, 1) != HAL_OK)
  {
    Error_Handler();
  }
  /* USER CODE BEGIN LTDC_Init 2 */

    __HAL_LTDC_RELOAD_IMMEDIATE_CONFIG(&hltdc);

    __HAL_LTDC_LAYER_ENABLE(&hltdc, LTDC_LAYER_1);
    __HAL_LTDC_LAYER_ENABLE(&hltdc, LTDC_LAYER_2);
    HAL_LTDC_EnableDither(&hltdc);
    __HAL_LTDC_ENABLE(&hltdc);

  /* USER CODE END LTDC_Init 2 */

}

static void MX_SPI5_Init(void)
{

  /* SPI5 parameter configuration*/
  hspi5.Instance = SPI5;
  hspi5.Init.Mode = SPI_MODE_MASTER;
  hspi5.Init.Direction = SPI_DIRECTION_2LINES;
  hspi5.Init.DataSize = SPI_DATASIZE_8BIT;
  hspi5.Init.CLKPolarity = SPI_POLARITY_LOW;
  hspi5.Init.CLKPhase = SPI_PHASE_1EDGE;
  hspi5.Init.NSS = SPI_NSS_SOFT;
  hspi5.Init.BaudRatePrescaler = SPI_BAUDRATEPRESCALER_16;
  hspi5.Init.FirstBit = SPI_FIRSTBIT_MSB;
  hspi5.Init.TIMode = SPI_TIMODE_DISABLE;
  hspi5.Init.CRCCalculation = SPI_CRCCALCULATION_DISABLE;
  hspi5.Init.CRCPolynomial = 10;
  if (HAL_SPI_Init(&hspi5) != HAL_OK)
  {
    Error_Handler();
  }

}

static void MX_TIM2_Init(void)
{

  TIM_ClockConfigTypeDef sClockSourceConfig = {0};
  TIM_MasterConfigTypeDef sMasterConfig = {0};

  htim2.Instance = TIM2;
  htim2.Init.Prescaler = 499;
  htim2.Init.CounterMode = TIM_COUNTERMODE_UP;
  htim2.Init.Period = 1439;
  htim2.Init.ClockDivision = TIM_CLOCKDIVISION_DIV1;
  htim2.Init.AutoReloadPreload = TIM_AUTORELOAD_PRELOAD_ENABLE;
  if (HAL_TIM_Base_Init(&htim2) != HAL_OK)
  {
    Error_Handler();
  }
  sClockSourceConfig.ClockSource = TIM_CLOCKSOURCE_INTERNAL;
  if (HAL_TIM_ConfigClockSource(&htim2, &sClockSourceConfig) != HAL_OK)
  {
    Error_Handler();
  }
  sMasterConfig.MasterOutputTrigger = TIM_TRGO_UPDATE;
  sMasterConfig.MasterSlaveMode = TIM_MASTERSLAVEMODE_DISABLE;
  if (HAL_TIMEx_MasterConfigSynchronization(&htim2, &sMasterConfig) != HAL_OK)
  {
    Error_Handler();
  }
  /* USER CODE BEGIN TIM2_Init 2 */
  while(__HAL_TIM_GET_FLAG(&htim2,0x1EFF)){
  	  __HAL_TIM_CLEAR_FLAG(&htim2,0x1EFF);	// Clear all flags
  	}
  /* USER CODE END TIM2_Init 2 */

}

static void MX_TIM4_Init(void)
{

  TIM_ClockConfigTypeDef sClockSourceConfig = {0};
  TIM_MasterConfigTypeDef sMasterConfig = {0};

  htim4.Instance = TIM4;
  htim4.Init.Prescaler = 0;
  htim4.Init.CounterMode = TIM_COUNTERMODE_UP;
  htim4.Init.Period = 1405;
  htim4.Init.ClockDivision = TIM_CLOCKDIVISION_DIV1;
  htim4.Init.AutoReloadPreload = TIM_AUTORELOAD_PRELOAD_DISABLE;
  if (HAL_TIM_Base_Init(&htim4) != HAL_OK)
  {
    Error_Handler();
  }
  sClockSourceConfig.ClockSource = TIM_CLOCKSOURCE_INTERNAL;
  if (HAL_TIM_ConfigClockSource(&htim4, &sClockSourceConfig) != HAL_OK)
  {
    Error_Handler();
  }
  sMasterConfig.MasterOutputTrigger = TIM_TRGO_UPDATE;
  sMasterConfig.MasterSlaveMode = TIM_MASTERSLAVEMODE_DISABLE;
  if (HAL_TIMEx_MasterConfigSynchronization(&htim4, &sMasterConfig) != HAL_OK)
  {
    Error_Handler();
  }

}

static void MX_TIM5_Init(void)
{

  TIM_ClockConfigTypeDef sClockSourceConfig = {0};
  TIM_MasterConfigTypeDef sMasterConfig = {0};

  htim5.Instance = TIM5;
  htim5.Init.Prescaler = 99;
  htim5.Init.CounterMode = TIM_COUNTERMODE_UP;
  htim5.Init.Period = 44;
  htim5.Init.ClockDivision = TIM_CLOCKDIVISION_DIV1;
  htim5.Init.AutoReloadPreload = TIM_AUTORELOAD_PRELOAD_DISABLE;
  if (HAL_TIM_Base_Init(&htim5) != HAL_OK)
  {
    Error_Handler();
  }
  sClockSourceConfig.ClockSource = TIM_CLOCKSOURCE_INTERNAL;
  if (HAL_TIM_ConfigClockSource(&htim5, &sClockSourceConfig) != HAL_OK)
  {
    Error_Handler();
  }
  sMasterConfig.MasterOutputTrigger = TIM_TRGO_UPDATE;
  sMasterConfig.MasterSlaveMode = TIM_MASTERSLAVEMODE_DISABLE;
  if (HAL_TIMEx_MasterConfigSynchronization(&htim5, &sMasterConfig) != HAL_OK)
  {
    Error_Handler();
  }
  /* USER CODE BEGIN TIM5_Init 2 */
  HAL_TIM_Base_Start_IT(&htim5);
  /* USER CODE END TIM5_Init 2 */

}

static void MX_USART1_UART_Init(void)
{

  huart1.Instance = USART1;
  huart1.Init.BaudRate = 115200;
  huart1.Init.WordLength = UART_WORDLENGTH_8B;
  huart1.Init.StopBits = UART_STOPBITS_1;
  huart1.Init.Parity = UART_PARITY_NONE;
  huart1.Init.Mode = UART_MODE_TX_RX;
  huart1.Init.HwFlowCtl = UART_HWCONTROL_NONE;
  huart1.Init.OverSampling = UART_OVERSAMPLING_16;
  if (HAL_UART_Init(&huart1) != HAL_OK)
  {
    Error_Handler();
  }

}

static void MX_DMA_Init(void)
{

  /* DMA controller clock enable */
  __HAL_RCC_DMA2_CLK_ENABLE();
  __HAL_RCC_DMA1_CLK_ENABLE();

  /* DMA interrupt init */
  /* DMA1_Stream6_IRQn interrupt configuration */
  HAL_NVIC_SetPriority(DMA1_Stream6_IRQn, 0, 0);
  HAL_NVIC_EnableIRQ(DMA1_Stream6_IRQn);
  /* DMA2_Stream0_IRQn interrupt configuration */
  HAL_NVIC_SetPriority(DMA2_Stream0_IRQn, 0, 0);
  HAL_NVIC_EnableIRQ(DMA2_Stream0_IRQn);

}

/* FMC initialization function */
static void MX_FMC_Init(void)
{

  FMC_SDRAM_TimingTypeDef SdramTiming = {0};

  /** Perform the SDRAM1 memory initialization sequence
  */
  hsdram1.Instance = FMC_SDRAM_DEVICE;
  /* hsdram1.Init */
  hsdram1.Init.SDBank = FMC_SDRAM_BANK2;
  hsdram1.Init.ColumnBitsNumber = FMC_SDRAM_COLUMN_BITS_NUM_8;
  hsdram1.Init.RowBitsNumber = FMC_SDRAM_ROW_BITS_NUM_12;
  hsdram1.Init.MemoryDataWidth = FMC_SDRAM_MEM_BUS_WIDTH_16;
  hsdram1.Init.InternalBankNumber = FMC_SDRAM_INTERN_BANKS_NUM_4;
  hsdram1.Init.CASLatency = FMC_SDRAM_CAS_LATENCY_3;
  hsdram1.Init.WriteProtection = FMC_SDRAM_WRITE_PROTECTION_DISABLE;
  hsdram1.Init.SDClockPeriod = FMC_SDRAM_CLOCK_PERIOD_2;
  hsdram1.Init.ReadBurst = FMC_SDRAM_RBURST_DISABLE;
  hsdram1.Init.ReadPipeDelay = FMC_SDRAM_RPIPE_DELAY_1;
  /* SdramTiming */
  SdramTiming.LoadToActiveDelay = 2;
  SdramTiming.ExitSelfRefreshDelay = 7;
  SdramTiming.SelfRefreshTime = 4;
  SdramTiming.RowCycleDelay = 7;
  SdramTiming.WriteRecoveryTime = 3;
  SdramTiming.RPDelay = 2;
  SdramTiming.RCDDelay = 2;

  if (HAL_SDRAM_Init(&hsdram1, &SdramTiming) != HAL_OK)
  {
    Error_Handler( );
  }

  /* USER CODE BEGIN FMC_Init 2 */
  SDRAM_InitSequence();
  /* USER CODE END FMC_Init 2 */
}

static void MX_GPIO_Init(void)
{
  GPIO_InitTypeDef GPIO_InitStruct = {0};

  /* GPIO Ports Clock Enable */
  __HAL_RCC_GPIOF_CLK_ENABLE();
  __HAL_RCC_GPIOH_CLK_ENABLE();
  __HAL_RCC_GPIOC_CLK_ENABLE();
  __HAL_RCC_GPIOA_CLK_ENABLE();
  __HAL_RCC_GPIOB_CLK_ENABLE();
  __HAL_RCC_GPIOG_CLK_ENABLE();
  __HAL_RCC_GPIOE_CLK_ENABLE();
  __HAL_RCC_GPIOD_CLK_ENABLE();

  /*Configure GPIO pin Output Level */
  HAL_GPIO_WritePin(GPIOC, NCS_MEMS_SPI_Pin|CSX_Pin, GPIO_PIN_RESET);

  /*Configure GPIO pin Output Level */
  HAL_GPIO_WritePin(TEST_OUT_GPIO_Port, TEST_OUT_Pin, GPIO_PIN_RESET);

  /*Configure GPIO pin Output Level */
  HAL_GPIO_WritePin(GPIOD, RDX_Pin|WRX_DCX_Pin, GPIO_PIN_RESET);

  /*Configure GPIO pin Output Level */
  HAL_GPIO_WritePin(GPIOG, LED_GREEN_Pin|LED_RED_Pin, GPIO_PIN_RESET);

  /*Configure GPIO pins : NCS_MEMS_SPI_Pin CSX_Pin */
  GPIO_InitStruct.Pin = NCS_MEMS_SPI_Pin|CSX_Pin;
  GPIO_InitStruct.Mode = GPIO_MODE_OUTPUT_PP;
  GPIO_InitStruct.Pull = GPIO_NOPULL;
  GPIO_InitStruct.Speed = GPIO_SPEED_FREQ_LOW;
  HAL_GPIO_Init(GPIOC, &GPIO_InitStruct);

  /*Configure GPIO pin : BLUE_BTN_Pin */
  GPIO_InitStruct.Pin = BLUE_BTN_Pin;
  GPIO_InitStruct.Mode = GPIO_MODE_INPUT;
  GPIO_InitStruct.Pull = GPIO_NOPULL;
  HAL_GPIO_Init(BLUE_BTN_GPIO_Port, &GPIO_InitStruct);

  /*Configure GPIO pin : TEST_OUT_Pin */
  GPIO_InitStruct.Pin = TEST_OUT_Pin;
  GPIO_InitStruct.Mode = GPIO_MODE_OUTPUT_PP;
  GPIO_InitStruct.Pull = GPIO_NOPULL;
  GPIO_InitStruct.Speed = GPIO_SPEED_FREQ_LOW;
  HAL_GPIO_Init(TEST_OUT_GPIO_Port, &GPIO_InitStruct);

  /*Configure GPIO pin : TE_Pin */
  GPIO_InitStruct.Pin = TE_Pin;
  GPIO_InitStruct.Mode = GPIO_MODE_INPUT;
  GPIO_InitStruct.Pull = GPIO_NOPULL;
  HAL_GPIO_Init(TE_GPIO_Port, &GPIO_InitStruct);

  /*Configure GPIO pins : RDX_Pin WRX_DCX_Pin */
  GPIO_InitStruct.Pin = RDX_Pin|WRX_DCX_Pin;
  GPIO_InitStruct.Mode = GPIO_MODE_OUTPUT_PP;
  GPIO_InitStruct.Pull = GPIO_NOPULL;
  GPIO_InitStruct.Speed = GPIO_SPEED_FREQ_LOW;
  HAL_GPIO_Init(GPIOD, &GPIO_InitStruct);

  /*Configure GPIO pins : LED_GREEN_Pin LED_RED_Pin */
  GPIO_InitStruct.Pin = LED_GREEN_Pin|LED_RED_Pin;
  GPIO_InitStruct.Mode = GPIO_MODE_OUTPUT_PP;
  GPIO_InitStruct.Pull = GPIO_NOPULL;
  GPIO_InitStruct.Speed = GPIO_SPEED_FREQ_LOW;
  HAL_GPIO_Init(GPIOG, &GPIO_InitStruct);

}

/* USER CODE BEGIN 4 */
void HAL_UART_RxCpltCallback(UART_HandleTypeDef *huart) {
	//printf("odebralem cokolwiek\r\n");

	if (Received == '1')

	{
		printf("Podaj nowa wartosc  1|2|3 [V]: \r\n");
		uint8_t value =0;
		HAL_UART_Receive(&huart1, &value, 1,HAL_MAX_DELAY);
		setup.trigger_treshold = (value-48)*4096/3.3;
		printf("value is: %d\r\n",setup.trigger_treshold);

	}
	else if (Received == '6')
	{

		if (stop_flag == 0) {
			printf("-------------------------------\r\n");
			printf("! ZATRZYMUJE - STOP ! \r\n");
			printf("-------------------------------\r\n");
			stop_flag = 1;
		} else if (stop_flag == 1) {
			printf("! START ! \r\n");
			stop_flag = 0;

		}

	}
	else if (Received == '4') {

		printf("Podaj nowa wartosc w zakresie 1-9[10-90Hz]: \r\n");
		uint8_t value =0;
		HAL_UART_Receive(&huart1, &value, 1,HAL_MAX_DELAY);
		frequency = (value-48)*10;
	}
	else if (Received == '2') {
		printf("-------------------------------\r\n");
		printf("0 - 5V/div \r\n");
		printf("1 - 2V/div \r\n");
		printf("2 - 1V/div \r\n");
		printf("3 - 0V5/div \r\n");
		printf("4 - 0V2/div \r\n");
		printf("5 - 0V1/div \r\n");
		printf("6 - 0V05/div \r\n");
		printf("Podaj nowa wartosc w zakresie 0-6: \r\n");

		uint8_t value =0;
		HAL_UART_Receive(&huart1, &value, 1,HAL_MAX_DELAY);
		setup.factor_value = (value-48);
	}
	else if (Received == '5') {
		printf("-------------------------------\r\n");
		printf("Podaj nowa wartosc w zakresie 1-9 [1.1-1.9V]: \r\n");
		uint8_t value =0;
		HAL_UART_Receive(&huart1, &value, 1,HAL_MAX_DELAY);
		voltage_amp = (value-48)+10;
	}
	else if (Received == '7') {

	float value = 0.0;
	value = (maxvalueindex+1)*1.0/512*1000;
	printf("-------------------------------\r\n");
		printf("Częstotliwość: %f Hz\r\n", value);
		printf("Mnimalne napiecie : %f\r\n", min_value_conv);
		printf("Maksymalne napiecie : %f\r\n", max_value_conv);
		float p2p = max_value_conv-min_value_conv;
		printf("Napiecie p2p : %f", p2p);
	}
	else
	{

	}

	ospa_menu_show();
	HAL_UART_Receive_IT(&huart1, &Received, 1); // Ponowne włączenie nasłuchiwania

}
/* USER CODE END 4 */

void Error_Handler(void)
{
  /* USER CODE BEGIN Error_Handler_Debug */
  /* User can add his own implementation to report the HAL error return state */

	HAL_GPIO_WritePin(LED_GREEN_GPIO_Port,LED_GREEN_Pin,SET);
	HAL_GPIO_WritePin(LED_RED_GPIO_Port,LED_RED_Pin,RESET);
while(1){
	HAL_Delay(100);
	HAL_GPIO_TogglePin(LED_GREEN_GPIO_Port,LED_GREEN_Pin );
	HAL_GPIO_TogglePin(LED_RED_GPIO_Port,LED_RED_Pin );

}
  /* USER CODE END Error_Handler_Debug */
}

/************************ (C) COPYRIGHT STMicroelectronics *****END OF FILE****/
